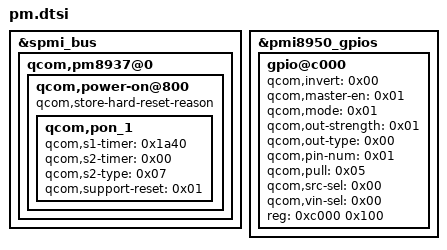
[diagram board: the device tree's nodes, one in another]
&spmi_bus {
	qcom,pm8937@0 {
		qcom,power-on@800 {
			qcom,store-hard-reset-reason;
			qcom,pon_1 {		
				qcom,s1-timer = < 0x1a40 >;
				qcom,s2-timer = < 0x00 >;
				qcom,s2-type = < 0x07 >;
				qcom,support-reset = < 0x01 >;
			};
		};
	};
};

&pmi8950_gpios {
					gpio@c000 {
						qcom,invert = < 0x00 >;
						qcom,master-en = < 0x01 >;
						qcom,mode = < 0x01 >;
						qcom,out-strength = < 0x01 >;
						qcom,out-type = < 0x00 >;
						qcom,pin-num = < 0x01 >;
						qcom,pull = < 0x05 >;
						qcom,src-sel = < 0x00 >;
						qcom,vin-sel = < 0x00 >;
						reg = < 0xc000 0x100 >;
						status = "okay";
					};
};
